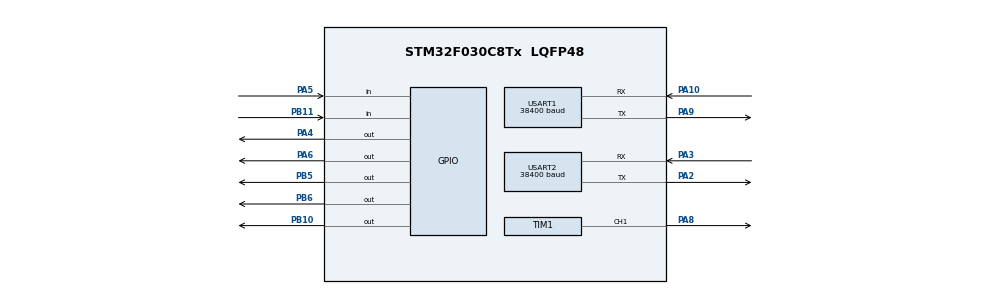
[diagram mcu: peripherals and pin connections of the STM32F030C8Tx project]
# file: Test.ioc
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Mcu.Family=STM32F0
Mcu.Name=STM32F030C8Tx
Mcu.Package=LQFP48
PA10.Mode=Asynchronous
PA10.Signal=USART1_RX
PA2.Mode=Asynchronous
PA2.Signal=USART2_TX
PA3.Mode=Asynchronous
PA3.Signal=USART2_RX
PA4.Signal=GPIO_Output
PA5.Signal=GPIO_Input
PA6.Signal=GPIO_Output
PA8.Signal=S_TIM1_CH1
PA9.Mode=Asynchronous
PA9.Signal=USART1_TX
PB10.Signal=GPIO_Output
PB11.Signal=GPIO_Input
PB5.Signal=GPIO_Output
PB6.Signal=GPIO_Output
ProjectManager.HeapSize=0x200
ProjectManager.StackSize=0x400
ProjectManager.TargetToolchain=STM32CubeIDE
SH.S_TIM1_CH1.0=TIM1_CH1,PWM Generation1 CH1
TIM1.Channel-PWM\ Generation1\ CH1=TIM_CHANNEL_1
TIM1.ClockDivision=TIM_CLOCKDIVISION_DIV1
TIM1.Period=20000-1
TIM1.Prescaler=8-1
USART1.BaudRate=38400
USART1.VirtualMode-Asynchronous=VM_ASYNC
USART2.BaudRate=38400
USART2.VirtualMode-Asynchronous=VM_ASYNC
VP_TIM1_VS_ClockSourceINT.Mode=Internal
board=custom

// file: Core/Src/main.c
/* USER CODE BEGIN Header */
/**
  ******************************************************************************
  * @file           : main.c
  * @brief          : Main program body
  ******************************************************************************
  * @attention
  *
  * Copyright (c) 2026 STMicroelectronics.
  * All rights reserved.
  *
  * This software is licensed under terms that can be found in the LICENSE file
  * in the root directory of this software component.
  * If no LICENSE file comes with this software, it is provided AS-IS.
  *
  ******************************************************************************
  */
/* USER CODE END Header */
#include "main.h"

TIM_HandleTypeDef htim1;

UART_HandleTypeDef huart1;
UART_HandleTypeDef huart2;

void SystemClock_Config(void);
static void MX_GPIO_Init(void);
static void MX_USART1_UART_Init(void);
static void MX_USART2_UART_Init(void);
static void MX_TIM1_Init(void);

int main(void)
{

  /* MCU Configuration--------------------------------------------------------*/

  /* Reset of all peripherals, Initializes the Flash interface and the Systick. */
  HAL_Init();

  /* Configure the system clock */
  SystemClock_Config();

  /* Initialize all configured peripherals */
  MX_GPIO_Init();
  MX_USART1_UART_Init();
  MX_USART2_UART_Init();
  MX_TIM1_Init();

  /* Infinite loop */
  /* USER CODE BEGIN WHILE */

  prj_Disp_init();

  while (1)
  {
    /* USER CODE END WHILE */

  }
}

void SystemClock_Config(void)
{
  RCC_OscInitTypeDef RCC_OscInitStruct = {0};
  RCC_ClkInitTypeDef RCC_ClkInitStruct = {0};
  RCC_PeriphCLKInitTypeDef PeriphClkInit = {0};

  /** Initializes the RCC Oscillators according to the specified parameters
  * in the RCC_OscInitTypeDef structure.
  */
  RCC_OscInitStruct.OscillatorType = RCC_OSCILLATORTYPE_HSI;
  RCC_OscInitStruct.HSIState = RCC_HSI_ON;
  RCC_OscInitStruct.HSICalibrationValue = RCC_HSICALIBRATION_DEFAULT;
  RCC_OscInitStruct.PLL.PLLState = RCC_PLL_NONE;
  if (HAL_RCC_OscConfig(&RCC_OscInitStruct) != HAL_OK)
  {
    Error_Handler();
  }

  /** Initializes the CPU, AHB and APB buses clocks
  */
  RCC_ClkInitStruct.ClockType = RCC_CLOCKTYPE_HCLK|RCC_CLOCKTYPE_SYSCLK
                              |RCC_CLOCKTYPE_PCLK1;
  RCC_ClkInitStruct.SYSCLKSource = RCC_SYSCLKSOURCE_HSI;
  RCC_ClkInitStruct.AHBCLKDivider = RCC_SYSCLK_DIV1;
  RCC_ClkInitStruct.APB1CLKDivider = RCC_HCLK_DIV1;

  if (HAL_RCC_ClockConfig(&RCC_ClkInitStruct, FLASH_LATENCY_0) != HAL_OK)
  {
    Error_Handler();
  }
  PeriphClkInit.PeriphClockSelection = RCC_PERIPHCLK_USART1;
  PeriphClkInit.Usart1ClockSelection = RCC_USART1CLKSOURCE_PCLK1;
  if (HAL_RCCEx_PeriphCLKConfig(&PeriphClkInit) != HAL_OK)
  {
    Error_Handler();
  }
}

static void MX_TIM1_Init(void)
{

  TIM_ClockConfigTypeDef sClockSourceConfig = {0};
  TIM_MasterConfigTypeDef sMasterConfig = {0};
  TIM_OC_InitTypeDef sConfigOC = {0};
  TIM_BreakDeadTimeConfigTypeDef sBreakDeadTimeConfig = {0};

  htim1.Instance = TIM1;
  htim1.Init.Prescaler = 8-1;
  htim1.Init.CounterMode = TIM_COUNTERMODE_UP;
  htim1.Init.Period = 20000-1;
  htim1.Init.ClockDivision = TIM_CLOCKDIVISION_DIV1;
  htim1.Init.RepetitionCounter = 0;
  htim1.Init.AutoReloadPreload = TIM_AUTORELOAD_PRELOAD_DISABLE;
  if (HAL_TIM_Base_Init(&htim1) != HAL_OK)
  {
    Error_Handler();
  }
  sClockSourceConfig.ClockSource = TIM_CLOCKSOURCE_INTERNAL;
  if (HAL_TIM_ConfigClockSource(&htim1, &sClockSourceConfig) != HAL_OK)
  {
    Error_Handler();
  }
  if (HAL_TIM_PWM_Init(&htim1) != HAL_OK)
  {
    Error_Handler();
  }
  sMasterConfig.MasterOutputTrigger = TIM_TRGO_RESET;
  sMasterConfig.MasterSlaveMode = TIM_MASTERSLAVEMODE_DISABLE;
  if (HAL_TIMEx_MasterConfigSynchronization(&htim1, &sMasterConfig) != HAL_OK)
  {
    Error_Handler();
  }
  sConfigOC.OCMode = TIM_OCMODE_PWM1;
  sConfigOC.Pulse = 0;
  sConfigOC.OCPolarity = TIM_OCPOLARITY_HIGH;
  sConfigOC.OCNPolarity = TIM_OCNPOLARITY_HIGH;
  sConfigOC.OCFastMode = TIM_OCFAST_DISABLE;
  sConfigOC.OCIdleState = TIM_OCIDLESTATE_RESET;
  sConfigOC.OCNIdleState = TIM_OCNIDLESTATE_RESET;
  if (HAL_TIM_PWM_ConfigChannel(&htim1, &sConfigOC, TIM_CHANNEL_1) != HAL_OK)
  {
    Error_Handler();
  }
  sBreakDeadTimeConfig.OffStateRunMode = TIM_OSSR_DISABLE;
  sBreakDeadTimeConfig.OffStateIDLEMode = TIM_OSSI_DISABLE;
  sBreakDeadTimeConfig.LockLevel = TIM_LOCKLEVEL_OFF;
  sBreakDeadTimeConfig.DeadTime = 0;
  sBreakDeadTimeConfig.BreakState = TIM_BREAK_DISABLE;
  sBreakDeadTimeConfig.BreakPolarity = TIM_BREAKPOLARITY_HIGH;
  sBreakDeadTimeConfig.AutomaticOutput = TIM_AUTOMATICOUTPUT_DISABLE;
  if (HAL_TIMEx_ConfigBreakDeadTime(&htim1, &sBreakDeadTimeConfig) != HAL_OK)
  {
    Error_Handler();
  }
  HAL_TIM_MspPostInit(&htim1);

}

static void MX_USART1_UART_Init(void)
{

  huart1.Instance = USART1;
  huart1.Init.BaudRate = 38400;
  huart1.Init.WordLength = UART_WORDLENGTH_8B;
  huart1.Init.StopBits = UART_STOPBITS_1;
  huart1.Init.Parity = UART_PARITY_NONE;
  huart1.Init.Mode = UART_MODE_TX_RX;
  huart1.Init.HwFlowCtl = UART_HWCONTROL_NONE;
  huart1.Init.OverSampling = UART_OVERSAMPLING_16;
  huart1.Init.OneBitSampling = UART_ONE_BIT_SAMPLE_DISABLE;
  huart1.AdvancedInit.AdvFeatureInit = UART_ADVFEATURE_NO_INIT;
  if (HAL_UART_Init(&huart1) != HAL_OK)
  {
    Error_Handler();
  }

}

static void MX_USART2_UART_Init(void)
{

  huart2.Instance = USART2;
  huart2.Init.BaudRate = 38400;
  huart2.Init.WordLength = UART_WORDLENGTH_8B;
  huart2.Init.StopBits = UART_STOPBITS_1;
  huart2.Init.Parity = UART_PARITY_NONE;
  huart2.Init.Mode = UART_MODE_TX_RX;
  huart2.Init.HwFlowCtl = UART_HWCONTROL_NONE;
  huart2.Init.OverSampling = UART_OVERSAMPLING_16;
  huart2.Init.OneBitSampling = UART_ONE_BIT_SAMPLE_DISABLE;
  huart2.AdvancedInit.AdvFeatureInit = UART_ADVFEATURE_NO_INIT;
  if (HAL_UART_Init(&huart2) != HAL_OK)
  {
    Error_Handler();
  }

}

static void MX_GPIO_Init(void)
{
  GPIO_InitTypeDef GPIO_InitStruct = {0};

  /* GPIO Ports Clock Enable */
  __HAL_RCC_GPIOA_CLK_ENABLE();
  __HAL_RCC_GPIOB_CLK_ENABLE();

  /*Configure GPIO pin Output Level */
  HAL_GPIO_WritePin(GPIOA, GPIO_PIN_4|GPIO_PIN_6, GPIO_PIN_RESET);

  /*Configure GPIO pin Output Level */
  HAL_GPIO_WritePin(GPIOB, GPIO_PIN_10|GPIO_PIN_5|GPIO_PIN_6, GPIO_PIN_RESET);

  /*Configure GPIO pins : PA4 PA6 */
  GPIO_InitStruct.Pin = GPIO_PIN_4|GPIO_PIN_6;
  GPIO_InitStruct.Mode = GPIO_MODE_OUTPUT_PP;
  GPIO_InitStruct.Pull = GPIO_NOPULL;
  GPIO_InitStruct.Speed = GPIO_SPEED_FREQ_LOW;
  HAL_GPIO_Init(GPIOA, &GPIO_InitStruct);

  /*Configure GPIO pin : PA5 */
  GPIO_InitStruct.Pin = GPIO_PIN_5;
  GPIO_InitStruct.Mode = GPIO_MODE_INPUT;
  GPIO_InitStruct.Pull = GPIO_NOPULL;
  HAL_GPIO_Init(GPIOA, &GPIO_InitStruct);

  /*Configure GPIO pins : PB10 PB5 PB6 */
  GPIO_InitStruct.Pin = GPIO_PIN_10|GPIO_PIN_5|GPIO_PIN_6;
  GPIO_InitStruct.Mode = GPIO_MODE_OUTPUT_PP;
  GPIO_InitStruct.Pull = GPIO_NOPULL;
  GPIO_InitStruct.Speed = GPIO_SPEED_FREQ_LOW;
  HAL_GPIO_Init(GPIOB, &GPIO_InitStruct);

  /*Configure GPIO pin : PB11 */
  GPIO_InitStruct.Pin = GPIO_PIN_11;
  GPIO_InitStruct.Mode = GPIO_MODE_INPUT;
  GPIO_InitStruct.Pull = GPIO_NOPULL;
  HAL_GPIO_Init(GPIOB, &GPIO_InitStruct);

}

void Error_Handler(void)
{
  __disable_irq();
  while (1)
  {
  }
}
